VERSION ""

NS_ :

BS_:

BU_:
VAL_TABLE_ Error_Code 1024 "IMD Powerstage disabled" 512 "AMS Powerstage disabled" 256 "Shutdown Circuit open" 128 "Pre-charge timeout" 64 "Current out of range" 32 "Current implausible" 16 "Battery voltage implausible" 8 "DC-Link Voltage implausible" 4 "Contactor Implausible" 2 "AMS Fault" 1 "IMD Fault" 0 "No Error" ;
VAL_TABLE_ TS_states 3 "Error" 2 "Operate" 1 "Pre-charging" 0 "Standby" ;
VAL_TABLE_ validity 1 "true" 0 "false" ;
VAL_TABLE_ ValueStatus 3 "Invalid - Open sensor wire" 2 "Invalid - Value out of range" 1 "Invalid - PEC error" 0 "Valid" ;
VAL_TABLE_ States 1 "Active" 0 "Inactive" ;
VAL_TABLE_ SlaveMultiplex 11 "Slave 12" 10 "Slave 11" 9 "Slave 10" 8 "Slave 9" 7 "Slave 8" 6 "Slave 7" 5 "Slave 6" 4 "Slave 5" 3 "Slave 4" 2 "Slave 3" 1 "Slave 2" 0 "Slave 1" ;

BO_ 3221225472 VECTOR__INDEPENDENT_SIG_MSG: 0 Vector__XXX
 SG_ SlaveMpx : 0|4@0+ (1,0) [0|11] "" Vector__XXX

BO_ 11 Balancing_Feedback: 2 Vector__XXX
 SG_ Balancing_gates : 3|12@0+ (1,0) [0|0] "" Vector__XXX
 SG_ SlaveMpx : 7|4@0+ (1,0) [0|11] "" Vector__XXX

BO_ 1 Startup: 4 Vector__XXX
 SG_ Reset_Reason : 7|32@0+ (1,0) [0|0] "" Vector__XXX

BO_ 15 Diag_Response: 8 Vector__XXX

BO_ 14 Diag_Request: 8 Vector__XXX

BO_ 0 TS_request: 2 Vector__XXX
 SG_ Request_Control : 0|1@0+ (1,0) [0|1] "" Vector__XXX
 SG_ TS_request : 15|8@0+ (1,0) [0|255] "" Vector__XXX

BO_ 13 Time: 8 Vector__XXX
 SG_ Uptime : 0|32@1+ (0.1,0) [0|429496729.5] "s" Vector__XXX
 SG_ SysTime : 32|32@1+ (1,0) [0|4294967295] "s" Vector__XXX

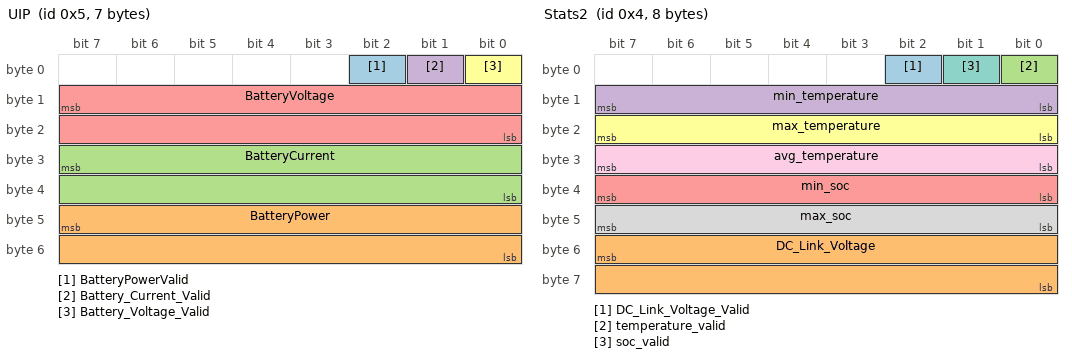
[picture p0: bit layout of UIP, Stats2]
BO_ 5 UIP: 7 Vector__XXX
 SG_ BatteryPowerValid : 2|1@0+ (1,0) [0|1] "" Vector__XXX
 SG_ BatteryPower : 47|16@0- (0.0025,0) [-81.92|81.9175] "kW" Vector__XXX
 SG_ BatteryCurrent : 31|16@0- (0.00625,0) [-200|200] "A" Vector__XXX
 SG_ Battery_Current_Valid : 1|1@0+ (1,0) [0|0] "" Vector__XXX
 SG_ BatteryVoltage : 15|16@0+ (0.1,0) [0|620] "V" Vector__XXX
 SG_ Battery_Voltage_Valid : 0|1@0+ (1,0) [0|0] "" Vector__XXX

BO_ 4 Stats2: 8 Vector__XXX
 SG_ DC_Link_Voltage_Valid : 2|1@0+ (1,0) [0|0] "" Vector__XXX
 SG_ DC_Link_Voltage : 55|16@0+ (0.1,0) [0|620] "V" Vector__XXX
 SG_ temperature_valid : 0|1@0+ (1,0) [0|0] "" Vector__XXX
 SG_ min_temperature : 15|8@0+ (0.5,0) [0|127.5] "°C" Vector__XXX
 SG_ min_soc : 39|8@0+ (1,0) [0|255] "%" Vector__XXX
 SG_ max_temperature : 23|8@0+ (0.5,0) [0|127.5] "°C" Vector__XXX
 SG_ soc_valid : 1|1@0+ (1,0) [0|0] "" Vector__XXX
 SG_ max_soc : 47|8@0+ (1,0) [0|255] "%" Vector__XXX
 SG_ avg_temperature : 31|8@0+ (0.5,0) [0|127.5] "°C" Vector__XXX

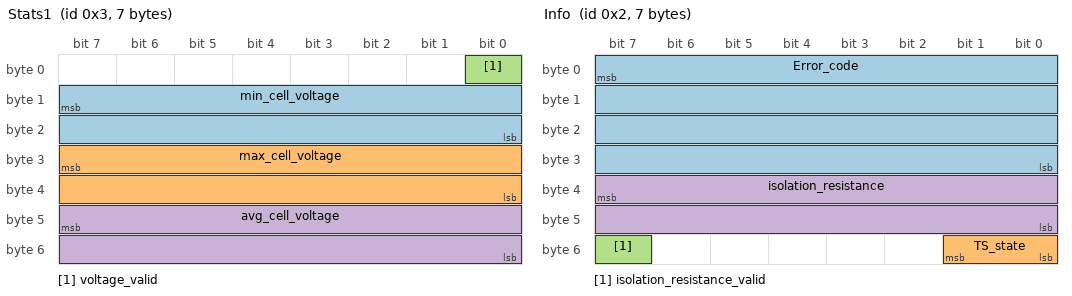
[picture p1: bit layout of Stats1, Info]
BO_ 3 Stats1: 7 Vector__XXX
 SG_ min_cell_voltage : 15|16@0+ (0.0001,0) [0|6.5535] "V" Vector__XXX
 SG_ max_cell_voltage : 31|16@0+ (0.0001,0) [0|6.5535] "V" Vector__XXX
 SG_ voltage_valid : 0|1@0+ (1,0) [0|0] "" Vector__XXX
 SG_ avg_cell_voltage : 47|16@0+ (0.0001,0) [0|6.5535] "V" Vector__XXX

BO_ 2 Info: 7 Vector__XXX
 SG_ Error_code : 7|32@0+ (1,0) [0|65535] "" Vector__XXX
 SG_ TS_state : 49|2@0+ (1,0) [0|0] "" Vector__XXX
 SG_ isolation_resistance_valid : 55|1@0+ (1,0) [0|0] "" Vector__XXX
 SG_ isolation_resistance : 39|16@0+ (1,0) [0|65535] "kOhm" Vector__XXX

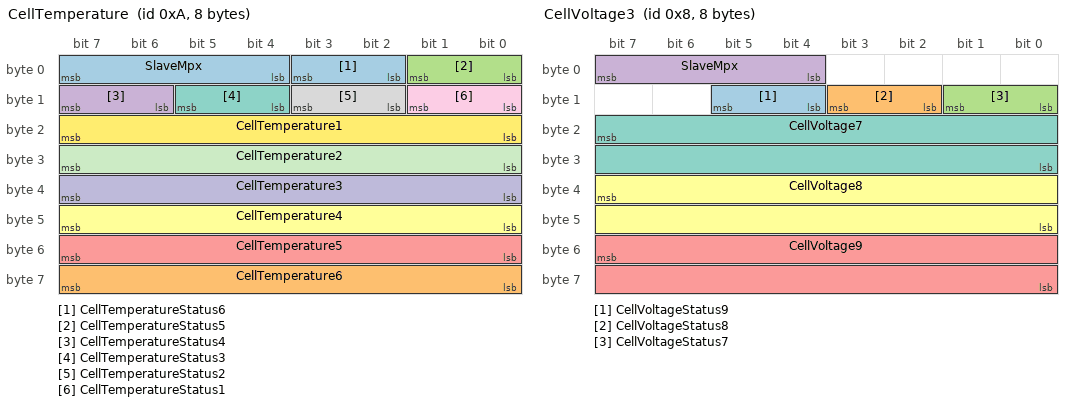
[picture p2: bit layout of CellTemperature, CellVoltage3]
BO_ 10 CellTemperature: 8 Vector__XXX
 SG_ CellTemperatureStatus6 : 3|2@0+ (1,0) [0|3] "" Vector__XXX
 SG_ CellTemperature6 : 63|8@0+ (0.5,0) [0|127.5] "°C" Vector__XXX
 SG_ CellTemperatureStatus5 : 1|2@0+ (1,0) [0|3] "" Vector__XXX
 SG_ CellTemperatureStatus4 : 15|2@0+ (1,0) [0|3] "" Vector__XXX
 SG_ CellTemperature5 : 55|8@0+ (0.5,0) [0|127.5] "°C" Vector__XXX
 SG_ CellTemperature4 : 47|8@0+ (0.5,0) [0|127.5] "°C" Vector__XXX
 SG_ CellTemperatureStatus3 : 13|2@0+ (1,0) [0|3] "" Vector__XXX
 SG_ CellTemperatureStatus2 : 11|2@0+ (1,0) [0|3] "" Vector__XXX
 SG_ CellTemperatureStatus1 : 9|2@0+ (1,0) [0|3] "" Vector__XXX
 SG_ CellTemperature3 : 39|8@0+ (0.5,0) [0|127.5] "°C" Vector__XXX
 SG_ CellTemperature2 : 31|8@0+ (0.5,0) [0|127.5] "°C" Vector__XXX
 SG_ CellTemperature1 : 23|8@0+ (0.5,0) [0|127.5] "°C" Vector__XXX
 SG_ SlaveMpx : 7|4@0+ (1,0) [0|11] "" Vector__XXX

BO_ 8 CellVoltage3: 8 Vector__XXX
 SG_ CellVoltageStatus9 : 13|2@0+ (1,0) [0|3] "" Vector__XXX
 SG_ CellVoltageStatus8 : 11|2@0+ (1,0) [0|3] "" Vector__XXX
 SG_ CellVoltageStatus7 : 9|2@0+ (1,0) [0|3] "" Vector__XXX
 SG_ SlaveMpx : 7|4@0+ (1,0) [0|11] "" Vector__XXX
 SG_ CellVoltage9 : 55|16@0+ (0.0001,0) [0|6.5535] "V" Vector__XXX
 SG_ CellVoltage8 : 39|16@0+ (0.0001,0) [0|6.5535] "V" Vector__XXX
 SG_ CellVoltage7 : 23|16@0+ (0.0001,0) [0|6.5535] "V" Vector__XXX

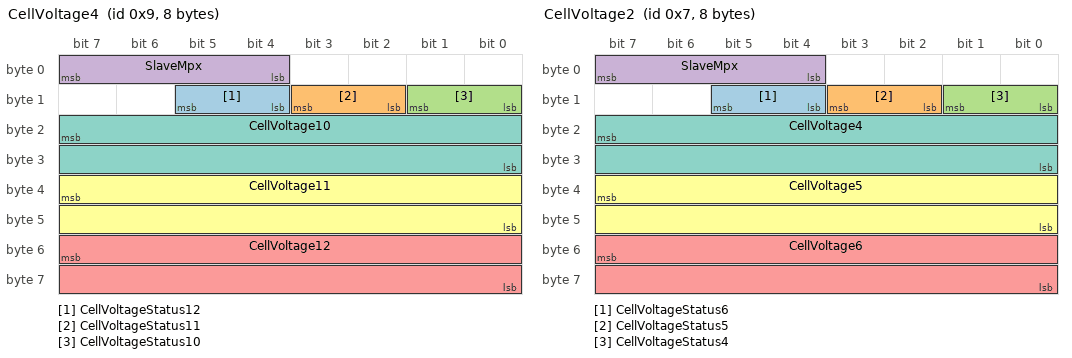
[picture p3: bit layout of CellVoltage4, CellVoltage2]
BO_ 9 CellVoltage4: 8 Vector__XXX
 SG_ CellVoltageStatus12 : 13|2@0+ (1,0) [0|3] "" Vector__XXX
 SG_ CellVoltageStatus11 : 11|2@0+ (1,0) [0|3] "" Vector__XXX
 SG_ CellVoltageStatus10 : 9|2@0+ (1,0) [0|3] "" Vector__XXX
 SG_ SlaveMpx : 7|4@0+ (1,0) [0|11] "" Vector__XXX
 SG_ CellVoltage12 : 55|16@0+ (0.0001,0) [0|6.5535] "V" Vector__XXX
 SG_ CellVoltage11 : 39|16@0+ (0.0001,0) [0|6.5535] "V" Vector__XXX
 SG_ CellVoltage10 : 23|16@0+ (0.0001,0) [0|6.5535] "V" Vector__XXX

BO_ 7 CellVoltage2: 8 Vector__XXX
 SG_ CellVoltageStatus6 : 13|2@0+ (1,0) [0|3] "" Vector__XXX
 SG_ CellVoltageStatus5 : 11|2@0+ (1,0) [0|3] "" Vector__XXX
 SG_ CellVoltageStatus4 : 9|2@0+ (1,0) [0|3] "" Vector__XXX
 SG_ SlaveMpx : 7|4@0+ (1,0) [0|11] "" Vector__XXX
 SG_ CellVoltage6 : 55|16@0+ (0.0001,0) [0|6.5535] "V" Vector__XXX
 SG_ CellVoltage5 : 39|16@0+ (0.0001,0) [0|6.5535] "V" Vector__XXX
 SG_ CellVoltage4 : 23|16@0+ (0.0001,0) [0|6.5535] "V" Vector__XXX

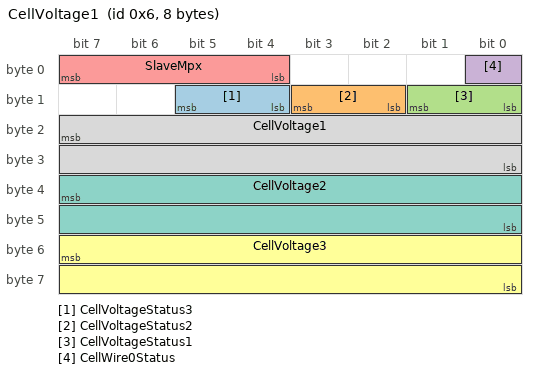
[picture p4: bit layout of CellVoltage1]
BO_ 6 CellVoltage1: 8 Vector__XXX
 SG_ CellVoltageStatus3 : 13|2@0+ (1,0) [0|3] "" Vector__XXX
 SG_ CellVoltageStatus2 : 11|2@0+ (1,0) [0|3] "" Vector__XXX
 SG_ CellVoltageStatus1 : 9|2@0+ (1,0) [0|3] "" Vector__XXX
 SG_ CellWire0Status : 0|1@1- (1,0) [0|0] "" Vector__XXX
 SG_ SlaveMpx : 7|4@0+ (1,0) [0|11] "" Vector__XXX
 SG_ CellVoltage3 : 55|16@0+ (0.0001,0) [0|6.5535] "V" Vector__XXX
 SG_ CellVoltage2 : 39|16@0+ (0.0001,0) [0|6.5535] "V" Vector__XXX
 SG_ CellVoltage1 : 23|16@0+ (0.0001,0) [0|6.5535] "V" Vector__XXX

BO_ 12 UniqueID: 5 Vector__XXX
 SG_ SlaveMpx : 7|4@0+ (1,0) [0|11] "" Vector__XXX
 SG_ UID : 15|32@0+ (1,0) [0|4294967295] "" Vector__XXX

CM_ BO_ 3221225472 "This is a message for not used signals, created by Vector CANdb++ DBC OLE DB Provider.";
CM_ SG_ 11 Balancing_gates "Bit coded; Each bit represents one cell.
LSB = Cell 1
MSB = Cell 12";
CM_ BO_ 1 "Message is sent on startup";
CM_ BO_ 15 "See Spreadsheet for protocol documentation";
CM_ BO_ 14 "See Spreadsheet for protocol documentation";
CM_ SG_ 0 Request_Control "0 = TS request only possible on Vehicle Bus
1 = TS request only possible on Diag Bus

This message has to be sent faster than 500 ms in case the value = 1. Otherwise a timeout is generated which gives the control back to the Vehicle Bus.";
CM_ SG_ 0 TS_request "0xFF = On
Else = Off";
CM_ SG_ 13 SysTime "Unix timestamp";
CM_ SG_ 2 Error_code "Bit-coded. Multiple errors can occur at the same time.";
CM_ SG_ 6 CellWire0Status "0x0 = OK
0x1 = Open";
CM_ SG_ 12 UID "32 Bit unique ID";
BA_DEF_  "BusType" STRING ;
BA_DEF_DEF_  "BusType" "CAN";
VAL_ 3221225472 SlaveMpx 11 "Slave 12" 10 "Slave 11" 9 "Slave 10" 8 "Slave 9" 7 "Slave 8" 6 "Slave 7" 5 "Slave 6" 4 "Slave 5" 3 "Slave 4" 2 "Slave 3" 1 "Slave 2" 0 "Slave 1" ;
VAL_ 11 SlaveMpx 11 "Slave 12" 10 "Slave 11" 9 "Slave 10" 8 "Slave 9" 7 "Slave 8" 6 "Slave 7" 5 "Slave 6" 4 "Slave 5" 3 "Slave 4" 2 "Slave 3" 1 "Slave 2" 0 "Slave 1" ;
VAL_ 5 Battery_Current_Valid 1 "true" 0 "false" ;
VAL_ 5 Battery_Voltage_Valid 1 "true" 0 "false" ;
VAL_ 4 DC_Link_Voltage_Valid 1 "true" 0 "false" ;
VAL_ 4 temperature_valid 1 "true" 0 "false" ;
VAL_ 4 soc_valid 1 "true" 0 "false" ;
VAL_ 3 voltage_valid 1 "true" 0 "false" ;
VAL_ 2 Error_code 1024 "IMD Powerstage disabled" 512 "AMS Powerstage disabled" 256 "Shutdown Circuit open" 128 "Pre-charge timeout" 64 "Current out of range" 32 "Current implausible" 16 "Battery voltage implausible" 8 "DC-Link Voltage implausible" 4 "Contactor Implausible" 2 "AMS Fault" 1 "IMD Fault" 0 "No Error" ;
VAL_ 2 TS_state 3 "Error" 2 "Operate" 1 "Pre-charging" 0 "Standby" ;
VAL_ 2 isolation_resistance_valid 1 "true" 0 "false" ;
VAL_ 10 CellTemperatureStatus6 3 "Invalid - Open sensor wire" 2 "Invalid - Value out of range" 1 "Invalid - PEC error" 0 "Valid" ;
VAL_ 10 CellTemperatureStatus5 3 "Invalid - Open sensor wire" 2 "Invalid - Value out of range" 1 "Invalid - PEC error" 0 "Valid" ;
VAL_ 10 CellTemperatureStatus4 3 "Invalid - Open sensor wire" 2 "Invalid - Value out of range" 1 "Invalid - PEC error" 0 "Valid" ;
VAL_ 10 CellTemperatureStatus3 3 "Invalid - Open sensor wire" 2 "Invalid - Value out of range" 1 "Invalid - PEC error" 0 "Valid" ;
VAL_ 10 CellTemperatureStatus2 3 "Invalid - Open sensor wire" 2 "Invalid - Value out of range" 1 "Invalid - PEC error" 0 "Valid" ;
VAL_ 10 CellTemperatureStatus1 3 "Invalid - Open sensor wire" 2 "Invalid - Value out of range" 1 "Invalid - PEC error" 0 "Valid" ;
VAL_ 10 SlaveMpx 11 "Slave 12" 10 "Slave 11" 9 "Slave 10" 8 "Slave 9" 7 "Slave 8" 6 "Slave 7" 5 "Slave 6" 4 "Slave 5" 3 "Slave 4" 2 "Slave 3" 1 "Slave 2" 0 "Slave 1" ;
VAL_ 8 CellVoltageStatus9 3 "Invalid - Open sensor wire" 2 "Invalid - Value out of range" 1 "Invalid - PEC error" 0 "Valid" ;
VAL_ 8 CellVoltageStatus8 3 "Invalid - Open sensor wire" 2 "Invalid - Value out of range" 1 "Invalid - PEC error" 0 "Valid" ;
VAL_ 8 CellVoltageStatus7 3 "Invalid - Open sensor wire" 2 "Invalid - Value out of range" 1 "Invalid - PEC error" 0 "Valid" ;
VAL_ 8 SlaveMpx 11 "Slave 12" 10 "Slave 11" 9 "Slave 10" 8 "Slave 9" 7 "Slave 8" 6 "Slave 7" 5 "Slave 6" 4 "Slave 5" 3 "Slave 4" 2 "Slave 3" 1 "Slave 2" 0 "Slave 1" ;
VAL_ 9 CellVoltageStatus12 3 "Invalid - Open sensor wire" 2 "Invalid - Value out of range" 1 "Invalid - PEC error" 0 "Valid" ;
VAL_ 9 CellVoltageStatus11 3 "Invalid - Open sensor wire" 2 "Invalid - Value out of range" 1 "Invalid - PEC error" 0 "Valid" ;
VAL_ 9 CellVoltageStatus10 3 "Invalid - Open sensor wire" 2 "Invalid - Value out of range" 1 "Invalid - PEC error" 0 "Valid" ;
VAL_ 9 SlaveMpx 11 "Slave 12" 10 "Slave 11" 9 "Slave 10" 8 "Slave 9" 7 "Slave 8" 6 "Slave 7" 5 "Slave 6" 4 "Slave 5" 3 "Slave 4" 2 "Slave 3" 1 "Slave 2" 0 "Slave 1" ;
VAL_ 7 CellVoltageStatus6 3 "Invalid - Open sensor wire" 2 "Invalid - Value out of range" 1 "Invalid - PEC error" 0 "Valid" ;
VAL_ 7 CellVoltageStatus5 3 "Invalid - Open sensor wire" 2 "Invalid - Value out of range" 1 "Invalid - PEC error" 0 "Valid" ;
VAL_ 7 CellVoltageStatus4 3 "Invalid - Open sensor wire" 2 "Invalid - Value out of range" 1 "Invalid - PEC error" 0 "Valid" ;
VAL_ 7 SlaveMpx 11 "Slave 12" 10 "Slave 11" 9 "Slave 10" 8 "Slave 9" 7 "Slave 8" 6 "Slave 7" 5 "Slave 6" 4 "Slave 5" 3 "Slave 4" 2 "Slave 3" 1 "Slave 2" 0 "Slave 1" ;
VAL_ 6 CellVoltageStatus3 3 "Invalid - Open sensor wire" 2 "Invalid - Value out of range" 1 "Invalid - PEC error" 0 "Valid" ;
VAL_ 6 CellVoltageStatus2 3 "Invalid - Open sensor wire" 2 "Invalid - Value out of range" 1 "Invalid - PEC error" 0 "Valid" ;
VAL_ 6 CellVoltageStatus1 3 "Invalid - Open sensor wire" 2 "Invalid - Value out of range" 1 "Invalid - PEC error" 0 "Valid" ;
VAL_ 6 SlaveMpx 11 "Slave 12" 10 "Slave 11" 9 "Slave 10" 8 "Slave 9" 7 "Slave 8" 6 "Slave 7" 5 "Slave 6" 4 "Slave 5" 3 "Slave 4" 2 "Slave 3" 1 "Slave 2" 0 "Slave 1" ;
VAL_ 12 SlaveMpx 11 "Slave 12" 10 "Slave 11" 9 "Slave 10" 8 "Slave 9" 7 "Slave 8" 6 "Slave 7" 5 "Slave 6" 4 "Slave 5" 3 "Slave 4" 2 "Slave 3" 1 "Slave 2" 0 "Slave 1" ;
